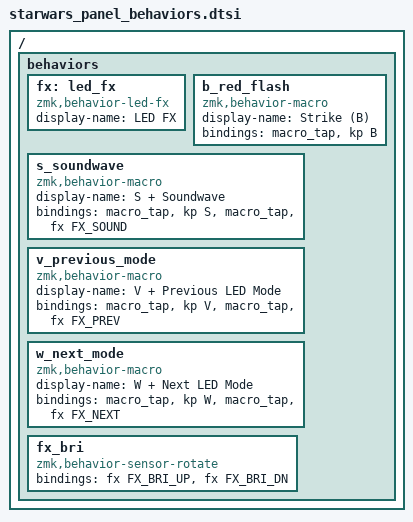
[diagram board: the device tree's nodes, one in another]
/*
 * LED effect behaviors (implemented in src/led_fx.c + src/behavior_led_fx.c).
 * The numbers below MUST match enum led_fx_cmd in src/led_fx.h.
 *
 *   &fx FX_RED       solid red (default; also selects the red palette)
 *   &fx FX_ALERT     flashing selected color; press again to return to solid
 *   &fx FX_CHASE     selected-color base with a bright pulse
 *   &fx FX_BREATHE   slow breathing in the selected color
 *   &fx FX_SCANNER   scanner in the selected color
 *   &fx FX_OFF       LEDs off
 *   &fx FX_SWEEP     one-shot bright pulse in the selected color, then back to the current effect
 *   &fx FX_WAVE      one-shot dark pulse across the strip, restoring each LED's current color
 *   &fx FX_NEXT      cycle to the next effect
 *   &fx FX_GREEN     select the green palette and solid effect
 *   &fx FX_PREV      cycle backward through effects
 *   &fx FX_FLASH     quick full-strip red flash, then restore the current effect
 *   &fx FX_FLASH_<COLOR>  same flash in green/blue/purple/white/yellow/orange/cyan/pink
 *   &fx FX_FLASH_SABER   flash the blade's current saber color (red when idle)
 *   &fx FX_SOUND     short cyan soundwave with irregular white twinkles
 *   &fx FX_STARFIELD random star-like twinkle across the strip
 *   &fx FX_METEOR    bright streak with a fading tail, alternating direction
 *   &fx FX_RIPPLE    two pulses expanding outward from the center
 *   &fx FX_DUAL_CHASE two pulses moving in opposite directions
 *   &fx FX_RAINBOW   full hue wheel sweeping along the path
 *   &fx FX_EQUALIZER pseudo-random spectrum-analyzer bars
 *   &fx FX_RAIN      multiple independent droplets with short trails
 *   &fx FX_SABER_IGNITE_BLUE / FX_SABER_IGNITE_RED ignite and flicker
 *   &fx FX_SABER_IGNITE_<COLOR>  ignite in green/purple/white/yellow/orange/cyan/pink
 *   &fx FX_SABER_DEACTIVATE extinguishes the saber and fades back to the prior mode
 *   &fx FX_BLUE / FX_PURPLE / FX_WHITE / FX_YELLOW / FX_ORANGE / FX_CYAN / FX_PINK
 *                    select that palette color and the solid effect
 *   &fx FX_COLOR_NEXT cycle the palette color, keeping the current effect
 *   &fx FX_BRI_UP / FX_BRI_DN   brightness (the encoder wrapper below uses these)
 *   &fx FX_BAR_NEXT / FX_BAR_PREV cycle the independent four-LED red light bar
 */

#define FX_RED     0
#define FX_ALERT   1
#define FX_CHASE   2
#define FX_BREATHE 3
#define FX_SCANNER 4
#define FX_OFF     5
#define FX_SWEEP   6
#define FX_NEXT    7
#define FX_BRI_UP  8
#define FX_BRI_DN  9
#define FX_WAVE    10
#define FX_GREEN   12
#define FX_PREV    13
#define FX_FLASH   14
#define FX_SOUND   15
#define FX_STARFIELD 16
#define FX_METEOR  17
#define FX_RIPPLE  18
#define FX_DUAL_CHASE 19
#define FX_RAINBOW 20
#define FX_EQUALIZER 21
#define FX_RAIN    22
#define FX_SABER_IGNITE_BLUE 23
#define FX_SABER_IGNITE_RED  24
#define FX_SABER_DEACTIVATE  25
#define FX_BLUE    26
#define FX_PURPLE  27
#define FX_WHITE   28
#define FX_YELLOW  29
#define FX_ORANGE  30
#define FX_CYAN    31
#define FX_PINK    32
#define FX_COLOR_NEXT 33
#define FX_SABER_IGNITE_GREEN  34
#define FX_SABER_IGNITE_PURPLE 35
#define FX_SABER_IGNITE_WHITE  36
#define FX_SABER_IGNITE_YELLOW 37
#define FX_SABER_IGNITE_ORANGE 38
#define FX_SABER_IGNITE_CYAN   39
#define FX_SABER_IGNITE_PINK   40
#define FX_FLASH_GREEN   41
#define FX_FLASH_BLUE    42
#define FX_FLASH_PURPLE  43
#define FX_FLASH_WHITE   44
#define FX_FLASH_YELLOW  45
#define FX_FLASH_ORANGE  46
#define FX_FLASH_CYAN    47
#define FX_FLASH_PINK    48
#define FX_FLASH_SABER   49
#define FX_BAR_NEXT      50
#define FX_BAR_PREV      51

/ {
	behaviors {
		fx: led_fx {
			compatible = "zmk,behavior-led-fx";
			#binding-cells = <1>;
			display-name = "LED FX";
		};

		/* Strike key. The DM console watches for B and sends the flash
		 * color that matches the ignited saber, so the key itself must
		 * not add a local red flash first. */
		b_red_flash: b_red_flash {
			compatible = "zmk,behavior-macro";
			#binding-cells = <0>;
			display-name = "Strike (B)";
			bindings =
				<&macro_tap &kp B>;
		};

		s_soundwave: s_soundwave {
			compatible = "zmk,behavior-macro";
			#binding-cells = <0>;
			display-name = "S + Soundwave";
			bindings =
				<&macro_tap &kp S>,
				<&macro_tap &fx FX_SOUND>;
		};

		v_previous_mode: v_previous_mode {
			compatible = "zmk,behavior-macro";
			#binding-cells = <0>;
			display-name = "V + Previous LED Mode";
			bindings =
				<&macro_tap &kp V>,
				<&macro_tap &fx FX_PREV>;
		};

		w_next_mode: w_next_mode {
			compatible = "zmk,behavior-macro";
			#binding-cells = <0>;
			display-name = "W + Next LED Mode";
			bindings =
				<&macro_tap &kp W>,
				<&macro_tap &fx FX_NEXT>;
		};

		/* Encoder-friendly brightness: clockwise = up, counter-clockwise = down */
		fx_bri: fx_bri {
			compatible = "zmk,behavior-sensor-rotate";
			#sensor-binding-cells = <0>;
			bindings = <&fx FX_BRI_UP>, <&fx FX_BRI_DN>;
		};
	};
};
